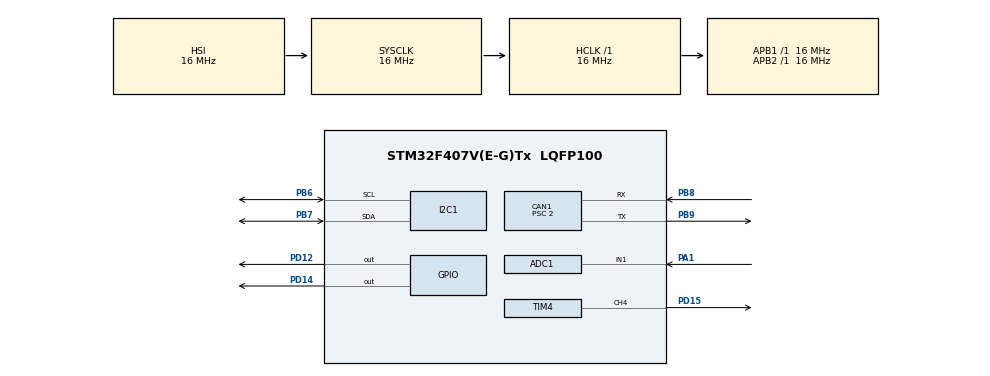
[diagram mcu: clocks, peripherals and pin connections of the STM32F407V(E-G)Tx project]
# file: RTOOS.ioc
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ADC1.Channel-0\#ChannelRegularConversion=ADC_CHANNEL_1
ADC1.ClockPrescaler=ADC_CLOCK_SYNC_PCLK_DIV4
ADC1.ContinuousConvMode=DISABLE
ADC1.DMAContinuousRequests=ENABLE
ADC1.ExternalTrigConv=ADC_EXTERNALTRIGCONV_T2_TRGO
ADC1.NbrOfConversion=1
ADC1.NbrOfConversionFlag=1
ADC1.Rank-0\#ChannelRegularConversion=1
ADC1.SamplingTime-0\#ChannelRegularConversion=ADC_SAMPLETIME_3CYCLES
ADC1.master=1
CAN1.BS1=CAN_BS1_13TQ
CAN1.BS2=CAN_BS2_2TQ
CAN1.CalculateBaudRate=500000
CAN1.CalculateTimeBit=2000
CAN1.CalculateTimeQuantum=125.0
CAN1.Prescaler=2
Dma.ADC1.0.Direction=DMA_PERIPH_TO_MEMORY
Dma.ADC1.0.FIFOMode=DMA_FIFOMODE_DISABLE
Dma.ADC1.0.Instance=DMA2_Stream0
Dma.ADC1.0.MemDataAlignment=DMA_MDATAALIGN_HALFWORD
Dma.ADC1.0.MemInc=DMA_MINC_DISABLE
Dma.ADC1.0.Mode=DMA_CIRCULAR
Dma.ADC1.0.PeriphDataAlignment=DMA_PDATAALIGN_HALFWORD
Dma.ADC1.0.PeriphInc=DMA_PINC_DISABLE
Dma.ADC1.0.Priority=DMA_PRIORITY_MEDIUM
Dma.Request0=ADC1
Mcu.Family=STM32F4
Mcu.Name=STM32F407V(E-G)Tx
Mcu.Package=LQFP100
NVIC.DMA2_Stream0_IRQn=true\:0\:0\:false\:false\:true\:false\:true\:true
NVIC.PriorityGroup=NVIC_PRIORITYGROUP_4
NVIC.TIM1_UP_TIM10_IRQn=true\:15\:0\:false\:false\:true\:false\:true\:true
NVIC.TimeBase=TIM1_UP_TIM10_IRQn
NVIC.TimeBaseIP=TIM1
PA1.Signal=ADCx_IN1
PB6.GPIO_Pu=GPIO_PULLUP
PB6.Mode=I2C
PB6.Signal=I2C1_SCL
PB7.GPIO_Pu=GPIO_PULLUP
PB7.Mode=I2C
PB7.Signal=I2C1_SDA
PB8.Mode=CAN_Activate
PB8.Signal=CAN1_RX
PB9.Mode=CAN_Activate
PB9.Signal=CAN1_TX
PD12.Signal=GPIO_Output
PD14.Signal=GPIO_Output
PD15.Signal=S_TIM4_CH4
ProjectManager.HeapSize=0x200
ProjectManager.StackSize=0x400
ProjectManager.TargetToolchain=STM32CubeIDE
RCC.AHBFreq_Value=16000000
RCC.APB1Freq_Value=16000000
RCC.APB2Freq_Value=16000000
RCC.CortexFreq_Value=16000000
RCC.HSE_VALUE=25000000
RCC.HSI_VALUE=16000000
RCC.LSE_VALUE=32768
RCC.SYSCLKFreq_VALUE=16000000
RCC.VCOOutputFreq_Value=192000000
SH.ADCx_IN1.0=ADC1_IN1,IN1
SH.S_TIM4_CH4.0=TIM4_CH4,PWM Generation4 CH4
TIM2.AutoReloadPreload=TIM_AUTORELOAD_PRELOAD_ENABLE
TIM2.Period=250
TIM2.Prescaler=16000-1
TIM2.TIM_MasterOutputTrigger=TIM_TRGO_UPDATE
TIM4.Channel-PWM\ Generation4\ CH4=TIM_CHANNEL_4
TIM4.Period=639
TIM4.Prescaler=0
VP_SYS_VS_tim1.Mode=TIM1
VP_TIM2_VS_ClockSourceINT.Mode=Internal
board=custom

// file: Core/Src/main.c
/* USER CODE BEGIN Header */
/**
  ******************************************************************************
  * @file           : main.c
  * @brief          : Main program body
  ******************************************************************************
  * @attention
  *
  * Copyright (c) 2026 STMicroelectronics.
  * All rights reserved.
  *
  * This software is licensed under terms that can be found in the LICENSE file
  * in the root directory of this software component.
  * If no LICENSE file comes with this software, it is provided AS-IS.
  *
  ******************************************************************************
  */
/* USER CODE END Header */
#include "main.h"

/* USER CODE BEGIN Includes */
#include "FreeRTOS.h"
#include "task.h"
#include "queue.h"
#include "semphr.h"

#define USE_FULL_ASSERT

/* USER CODE END Includes */

ADC_HandleTypeDef hadc1;
DMA_HandleTypeDef hdma_adc1;

CAN_HandleTypeDef hcan1;

I2C_HandleTypeDef hi2c1;

TIM_HandleTypeDef htim2;
TIM_HandleTypeDef htim4;

void SystemClock_Config(void);
static void MX_GPIO_Init(void);
static void MX_DMA_Init(void);
static void MX_TIM4_Init(void);
static void MX_I2C1_Init(void);
static void MX_ADC1_Init(void);
static void MX_TIM2_Init(void);
static void MX_CAN1_Init(void);

int main(void)
{

  /* MCU Configuration--------------------------------------------------------*/

  /* Reset of all peripherals, Initializes the Flash interface and the Systick. */
  HAL_Init();

  /* Configure the system clock */
  SystemClock_Config();

  /* Initialize all configured peripherals */
  MX_GPIO_Init();
  MX_DMA_Init();
  MX_TIM4_Init();
  MX_I2C1_Init();
  MX_ADC1_Init();
  MX_TIM2_Init();
  MX_CAN1_Init();
  /* USER CODE BEGIN 2 */

  HAL_TIM_Base_Start(&htim2);
  APP_System_Init();

  vTaskStartScheduler();

  /* USER CODE END 2 */

  /* Infinite loop */
  while (1)
  {

  }
}

void SystemClock_Config(void)
{
  RCC_OscInitTypeDef RCC_OscInitStruct = {0};
  RCC_ClkInitTypeDef RCC_ClkInitStruct = {0};

  /** Configure the main internal regulator output voltage
  */
  __HAL_RCC_PWR_CLK_ENABLE();
  __HAL_PWR_VOLTAGESCALING_CONFIG(PWR_REGULATOR_VOLTAGE_SCALE1);

  /** Initializes the RCC Oscillators according to the specified parameters
  * in the RCC_OscInitTypeDef structure.
  */
  RCC_OscInitStruct.OscillatorType = RCC_OSCILLATORTYPE_HSI;
  RCC_OscInitStruct.HSIState = RCC_HSI_ON;
  RCC_OscInitStruct.HSICalibrationValue = RCC_HSICALIBRATION_DEFAULT;
  RCC_OscInitStruct.PLL.PLLState = RCC_PLL_NONE;
  if (HAL_RCC_OscConfig(&RCC_OscInitStruct) != HAL_OK)
  {
    Error_Handler();
  }

  /** Initializes the CPU, AHB and APB buses clocks
  */
  RCC_ClkInitStruct.ClockType = RCC_CLOCKTYPE_HCLK|RCC_CLOCKTYPE_SYSCLK
                              |RCC_CLOCKTYPE_PCLK1|RCC_CLOCKTYPE_PCLK2;
  RCC_ClkInitStruct.SYSCLKSource = RCC_SYSCLKSOURCE_HSI;
  RCC_ClkInitStruct.AHBCLKDivider = RCC_SYSCLK_DIV1;
  RCC_ClkInitStruct.APB1CLKDivider = RCC_HCLK_DIV1;
  RCC_ClkInitStruct.APB2CLKDivider = RCC_HCLK_DIV1;

  if (HAL_RCC_ClockConfig(&RCC_ClkInitStruct, FLASH_LATENCY_0) != HAL_OK)
  {
    Error_Handler();
  }
}

static void MX_ADC1_Init(void)
{

  ADC_ChannelConfTypeDef sConfig = {0};

  /** Configure the global features of the ADC (Clock, Resolution, Data Alignment and number of conversion)
  */
  hadc1.Instance = ADC1;
  hadc1.Init.ClockPrescaler = ADC_CLOCK_SYNC_PCLK_DIV4;
  hadc1.Init.Resolution = ADC_RESOLUTION_12B;
  hadc1.Init.ScanConvMode = DISABLE;
  hadc1.Init.ContinuousConvMode = DISABLE;
  hadc1.Init.DiscontinuousConvMode = DISABLE;
  hadc1.Init.ExternalTrigConvEdge = ADC_EXTERNALTRIGCONVEDGE_RISING;
  hadc1.Init.ExternalTrigConv = ADC_EXTERNALTRIGCONV_T2_TRGO;
  hadc1.Init.DataAlign = ADC_DATAALIGN_RIGHT;
  hadc1.Init.NbrOfConversion = 1;
  hadc1.Init.DMAContinuousRequests = ENABLE;
  hadc1.Init.EOCSelection = ADC_EOC_SINGLE_CONV;
  if (HAL_ADC_Init(&hadc1) != HAL_OK)
  {
    Error_Handler();
  }

  /** Configure for the selected ADC regular channel its corresponding rank in the sequencer and its sample time.
  */
  sConfig.Channel = ADC_CHANNEL_1;
  sConfig.Rank = 1;
  sConfig.SamplingTime = ADC_SAMPLETIME_3CYCLES;
  if (HAL_ADC_ConfigChannel(&hadc1, &sConfig) != HAL_OK)
  {
    Error_Handler();
  }

}

static void MX_CAN1_Init(void)
{

  hcan1.Instance = CAN1;
  hcan1.Init.Prescaler = 2;
  hcan1.Init.Mode = CAN_MODE_NORMAL;
  hcan1.Init.SyncJumpWidth = CAN_SJW_1TQ;
  hcan1.Init.TimeSeg1 = CAN_BS1_13TQ;
  hcan1.Init.TimeSeg2 = CAN_BS2_2TQ;
  hcan1.Init.TimeTriggeredMode = DISABLE;
  hcan1.Init.AutoBusOff = DISABLE;
  hcan1.Init.AutoWakeUp = DISABLE;
  hcan1.Init.AutoRetransmission = DISABLE;
  hcan1.Init.ReceiveFifoLocked = DISABLE;
  hcan1.Init.TransmitFifoPriority = DISABLE;
  if (HAL_CAN_Init(&hcan1) != HAL_OK)
  {
    Error_Handler();
  }

}

static void MX_I2C1_Init(void)
{

  hi2c1.Instance = I2C1;
  hi2c1.Init.ClockSpeed = 100000;
  hi2c1.Init.DutyCycle = I2C_DUTYCYCLE_2;
  hi2c1.Init.OwnAddress1 = 0;
  hi2c1.Init.AddressingMode = I2C_ADDRESSINGMODE_7BIT;
  hi2c1.Init.DualAddressMode = I2C_DUALADDRESS_DISABLE;
  hi2c1.Init.OwnAddress2 = 0;
  hi2c1.Init.GeneralCallMode = I2C_GENERALCALL_DISABLE;
  hi2c1.Init.NoStretchMode = I2C_NOSTRETCH_DISABLE;
  if (HAL_I2C_Init(&hi2c1) != HAL_OK)
  {
    Error_Handler();
  }

}

static void MX_TIM2_Init(void)
{

  TIM_ClockConfigTypeDef sClockSourceConfig = {0};
  TIM_MasterConfigTypeDef sMasterConfig = {0};

  htim2.Instance = TIM2;
  htim2.Init.Prescaler = 16000-1;
  htim2.Init.CounterMode = TIM_COUNTERMODE_UP;
  htim2.Init.Period = 250;
  htim2.Init.ClockDivision = TIM_CLOCKDIVISION_DIV1;
  htim2.Init.AutoReloadPreload = TIM_AUTORELOAD_PRELOAD_ENABLE;
  if (HAL_TIM_Base_Init(&htim2) != HAL_OK)
  {
    Error_Handler();
  }
  sClockSourceConfig.ClockSource = TIM_CLOCKSOURCE_INTERNAL;
  if (HAL_TIM_ConfigClockSource(&htim2, &sClockSourceConfig) != HAL_OK)
  {
    Error_Handler();
  }
  sMasterConfig.MasterOutputTrigger = TIM_TRGO_UPDATE;
  sMasterConfig.MasterSlaveMode = TIM_MASTERSLAVEMODE_DISABLE;
  if (HAL_TIMEx_MasterConfigSynchronization(&htim2, &sMasterConfig) != HAL_OK)
  {
    Error_Handler();
  }

}

static void MX_TIM4_Init(void)
{

  TIM_MasterConfigTypeDef sMasterConfig = {0};
  TIM_OC_InitTypeDef sConfigOC = {0};

  htim4.Instance = TIM4;
  htim4.Init.Prescaler = 0;
  htim4.Init.CounterMode = TIM_COUNTERMODE_UP;
  htim4.Init.Period = 639;
  htim4.Init.ClockDivision = TIM_CLOCKDIVISION_DIV1;
  htim4.Init.AutoReloadPreload = TIM_AUTORELOAD_PRELOAD_DISABLE;
  if (HAL_TIM_PWM_Init(&htim4) != HAL_OK)
  {
    Error_Handler();
  }
  sMasterConfig.MasterOutputTrigger = TIM_TRGO_RESET;
  sMasterConfig.MasterSlaveMode = TIM_MASTERSLAVEMODE_DISABLE;
  if (HAL_TIMEx_MasterConfigSynchronization(&htim4, &sMasterConfig) != HAL_OK)
  {
    Error_Handler();
  }
  sConfigOC.OCMode = TIM_OCMODE_PWM1;
  sConfigOC.Pulse = 0;
  sConfigOC.OCPolarity = TIM_OCPOLARITY_HIGH;
  sConfigOC.OCFastMode = TIM_OCFAST_DISABLE;
  if (HAL_TIM_PWM_ConfigChannel(&htim4, &sConfigOC, TIM_CHANNEL_4) != HAL_OK)
  {
    Error_Handler();
  }
  HAL_TIM_MspPostInit(&htim4);

}

static void MX_DMA_Init(void)
{

  /* DMA controller clock enable */
  __HAL_RCC_DMA2_CLK_ENABLE();

  /* DMA interrupt init */
  /* DMA2_Stream0_IRQn interrupt configuration */
  HAL_NVIC_SetPriority(DMA2_Stream0_IRQn, 0, 0);
  HAL_NVIC_EnableIRQ(DMA2_Stream0_IRQn);

}

static void MX_GPIO_Init(void)
{
  GPIO_InitTypeDef GPIO_InitStruct = {0};

  /* GPIO Ports Clock Enable */
  __HAL_RCC_GPIOA_CLK_ENABLE();
  __HAL_RCC_GPIOD_CLK_ENABLE();
  __HAL_RCC_GPIOB_CLK_ENABLE();

  /*Configure GPIO pin Output Level */
  HAL_GPIO_WritePin(GPIOD, GPIO_PIN_12|GPIO_PIN_14, GPIO_PIN_RESET);

  /*Configure GPIO pins : PD12 PD14 */
  GPIO_InitStruct.Pin = GPIO_PIN_12|GPIO_PIN_14;
  GPIO_InitStruct.Mode = GPIO_MODE_OUTPUT_PP;
  GPIO_InitStruct.Pull = GPIO_NOPULL;
  GPIO_InitStruct.Speed = GPIO_SPEED_FREQ_LOW;
  HAL_GPIO_Init(GPIOD, &GPIO_InitStruct);

}

void HAL_TIM_PeriodElapsedCallback(TIM_HandleTypeDef *htim)
{
  if (htim->Instance == TIM1)
  {
    HAL_IncTick();
  }
}

void Error_Handler(void)
{
  __disable_irq();
  while (1)
  {
  }
}
